VERSION ""

NS_ :

BS_:

BU_: IPC GWM BCM
VAL_TABLE_ TP_Data_Rq 15 "Data15" 14 "Data14" 13 "Data13" 12 "Data12" 11 "Data11" 10 "Data10" 9 "Data9" 8 "Data8" 7 "Data7" 6 "Data6" 5 "Data5" 4 "Data4" 3 "Data3" 2 "Data2" 1 "Data1" 0 "Unused" ;
VAL_TABLE_ TA_Data_Rq 3 "Unavailable" 2 "Available" 1 "None" 0 "Not_Used" ;
VAL_TABLE_ ENV_Menu_scrn_1_Data 3 "Not_Used" 2 "ON" 1 "OFF" 0 "No_Menu" ;
VAL_TABLE_ ENV_Artst_Name_1_Rq 7 "Artist7" 6 "Artist6" 5 "Artist5" 4 "Artist4" 3 "Artist3" 2 "Artist2" 1 "Artist1" 0 "Not_Used" ;
VAL_TABLE_ ENV_Radio_Txt_1_Rq 0 "No_Message" 1 "Message1" 2 "Message2" 3 "Message3" 4 "Message4" 5 "Message5" 6 "Message6" 7 "Message7" 8 "Message8" 9 "Message9" 10 "Message10" 11 "Message11" 12 "Message12" 13 "Message13" 14 "Message14" 15 "Message15" ;
VAL_TABLE_ ENV_OFF_RUN 1 "RUN" 0 "OFF" ;
VAL_TABLE_ ENV_Preset_6_Bank_Rq 0 "Preset_6_None" 1 "Preset_6_One" 2 "Preset_6_Two" 3 "Preset_6_Three" 4 "Preset_6_Four" 5 "Preset_6_Five" 6 "Preset_6_Six" 7 "Preset_6_Seven" ;
VAL_TABLE_ ENV_Preset_12_Bank_Rq 0 "Preset_12_None" 1 "Preset_12_One" 2 "Preset_12_Two" 3 "Preset_12_Three" 4 "Preset_12_Four" 5 "Preset_12_Five" 6 "Preset_12_Six" 7 "Preset_12_Seven" 8 "Preset_12_Eight" 9 "Preset_12_Nine" 10 "Preset_12_Ten" 11 "Preset_12_Eleven" 12 "Preset_12_Twelve" 13 "Not_Used1" 14 "Not_Used2" 15 "Not_Used3" ;
VAL_TABLE_ ENV_Unavailabe_Availabled 3 "Disabled" 2 "ON" 1 "OFF" 0 "Unavailable" ;
VAL_TABLE_ ENV_HMI_MID_Sgnl_3_Rq 0 "Zero_Sig_3" 1 "One_Sig_3" 2 "Two_Sig_3" 3 "Three_Sig_3" 4 "Four_Sig_3" 5 "Five_Sig_3" 6 "Six_Sig_3" 7 "Seven_Sig_3" 8 "Eight_Sig_3" 9 "Nine_Sig_3" 10 "Ten_Sig_3" 11 "Eleven_Sig_3" 12 "Twelve_Sig_3" 13 "Thirteen_Sig_3" 14 "Fourteen_Sig_3" 15 "Fifteen_Sig_3" ;
VAL_TABLE_ ENV_ON_OFF 1 "ON" 0 "OFF" ;
VAL_TABLE_ ENV_HMI_MID_Sgnl_2_Rq 15 "Fifteen_Sig_2" 14 "Fourteen_Sig_2" 13 "Thirteen_Sig_2" 12 "Twelve_Sig_2" 11 "Eleven_Sig_2" 10 "Ten_Sig_2" 9 "Nine_Sig_2" 8 "Eight_Sig_2" 7 "Seven_Sig_2" 6 "Six_Sig_2" 5 "Five_Sig_2" 4 "Four_Sig_2" 3 "Three_Sig_2" 2 "Two_Sig_2" 1 "One_Sig_2" 0 "Zero_Sig_2" ;
VAL_TABLE_ ENV_HMI_MID_Sgnl_1_Rq 15 "Fifteen_Sig_1" 14 "Fourteen_Sig_1" 13 "Thirteen_Sig_1" 12 "Twelve_Sig_1" 11 "Eleven_Sig_1" 10 "Ten_Sig_1" 9 "Nine_Sig_1" 8 "Eight_Sig_1" 7 "Seven_Sig_1" 6 "Six_Sig_1" 5 "Five_Sig_1" 4 "Four_Sig_1" 3 "Three_Sig_1" 2 "Two_Sig_1" 1 "One_Sig_1" 0 "Zero_Sig_1" ;

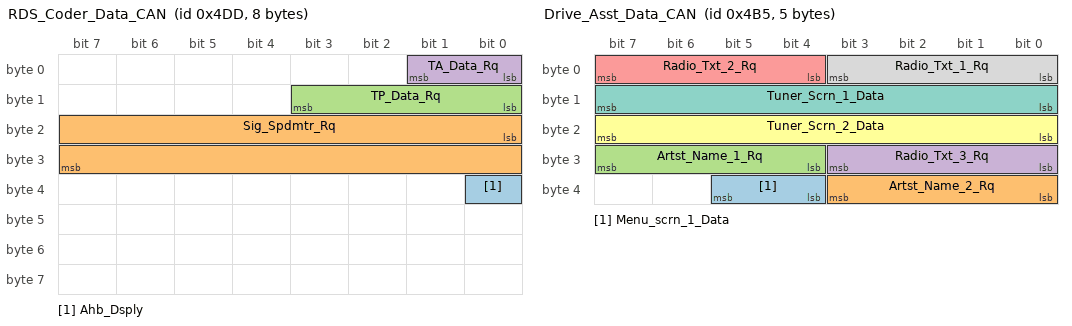
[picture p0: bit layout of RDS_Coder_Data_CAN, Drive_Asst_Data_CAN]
BO_ 1245 RDS_Coder_Data_CAN: 8 GWM
 SG_ Ahb_Dsply : 32|1@1+ (1,0) [0|1] ""  IPC
 SG_ Sig_Spdmtr_Rq : 16|16@1+ (1,0) [0|240] "SED"  IPC
 SG_ TP_Data_Rq : 8|4@1+ (1,0) [0|15] "SED"  IPC
 SG_ TA_Data_Rq : 0|2@1+ (1,0) [0|3] "SED"  IPC

BO_ 1205 Drive_Asst_Data_CAN: 5 BCM
 SG_ Menu_scrn_1_Data : 36|2@1+ (1,0) [0|3] "SED"  IPC
 SG_ Artst_Name_2_Rq : 32|4@1+ (1,0) [0|7] "SED"  IPC
 SG_ Artst_Name_1_Rq : 28|4@1+ (1,0) [0|7] "SED"  IPC
 SG_ Radio_Txt_3_Rq : 24|4@1+ (1,0) [0|15] "SED"  IPC
 SG_ Radio_Txt_2_Rq : 4|4@1+ (1,0) [0|15] "SED"  IPC
 SG_ Tuner_Scrn_2_Data : 16|8@1+ (1,0) [0|255] "Hz"  IPC
 SG_ Tuner_Scrn_1_Data : 8|8@1+ (1,0) [0|255] "Hz"  IPC
 SG_ Radio_Txt_1_Rq : 0|4@1+ (1,0) [0|15] "SED"  IPC

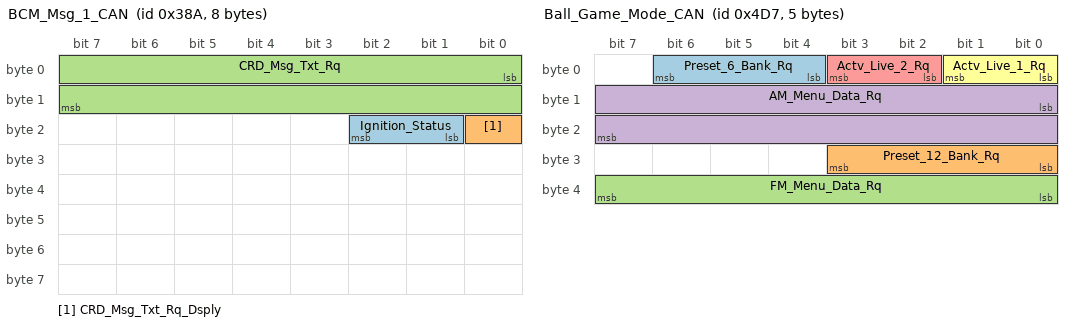
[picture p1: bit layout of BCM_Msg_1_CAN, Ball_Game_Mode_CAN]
BO_ 906 BCM_Msg_1_CAN: 8 BCM
 SG_ Ignition_Status : 17|2@1+ (1,0) [0|3] ""  IPC
 SG_ CRD_Msg_Txt_Rq_Dsply : 16|1@1+ (1,0) [0|1] "SED"  IPC
 SG_ CRD_Msg_Txt_Rq : 0|16@1+ (1,0) [0|65535] ""  IPC

BO_ 1239 Ball_Game_Mode_CAN: 5 GWM
 SG_ Preset_6_Bank_Rq : 4|3@1+ (1,0) [0|7] "SED"  IPC
 SG_ Preset_12_Bank_Rq : 24|4@1+ (1,0) [0|15] "SED"  IPC
 SG_ FM_Menu_Data_Rq : 32|8@1+ (1,0) [0|255] "SED"  IPC
 SG_ AM_Menu_Data_Rq : 8|16@1+ (1,0) [0|65535] ""  IPC
 SG_ Actv_Live_2_Rq : 2|2@1+ (1,0) [0|3] "SED"  IPC
 SG_ Actv_Live_1_Rq : 0|2@1+ (1,0) [0|3] "SED"  IPC

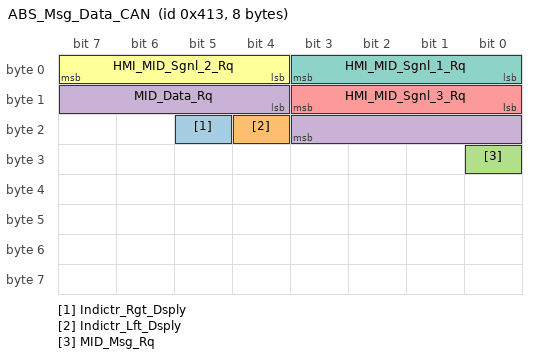
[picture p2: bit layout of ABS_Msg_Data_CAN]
BO_ 1043 ABS_Msg_Data_CAN: 8 GWM
 SG_ Indictr_Rgt_Dsply : 21|1@1+ (1,0) [0|1] ""  IPC
 SG_ Indictr_Lft_Dsply : 20|1@1+ (1,0) [0|1] ""  IPC
 SG_ MID_Msg_Rq : 24|1@1+ (1,0) [0|1] "SED"  IPC
 SG_ MID_Data_Rq : 12|8@1+ (1,0) [0|255] "range"  IPC
 SG_ HMI_MID_Sgnl_3_Rq : 8|4@1+ (1,0) [0|15] "SED"  IPC
 SG_ HMI_MID_Sgnl_2_Rq : 4|4@1+ (1,0) [0|15] "SED"  IPC
 SG_ HMI_MID_Sgnl_1_Rq : 0|4@1+ (1,0) [0|15] "SED"  IPC

BA_DEF_ BO_  "GenMsgCycleTime" INT 0 20000;
BA_DEF_ BO_  "GenMsgSendType" ENUM  "NA","Event","EventPeriodic","FixedPeriodic";
BA_DEF_DEF_  "GenMsgCycleTime" 0;
BA_DEF_DEF_  "GenMsgSendType" "NA";
BA_ "GenMsgSendType" BO_ 1245 1;
BA_ "GenMsgSendType" BO_ 1205 2;
BA_ "GenMsgCycleTime" BO_ 1205 1000;
BA_ "GenMsgSendType" BO_ 906 3;
BA_ "GenMsgCycleTime" BO_ 906 100;
BA_ "GenMsgSendType" BO_ 1239 3;
BA_ "GenMsgCycleTime" BO_ 1239 50;
BA_ "GenMsgSendType" BO_ 1043 2;
BA_ "GenMsgCycleTime" BO_ 1043 1500;
VAL_ 1245 Ahb_Dsply 1 "ON" 0 "OFF" ;
VAL_ 1245 TP_Data_Rq 15 "Data15" 14 "Data14" 13 "Data13" 12 "Data12" 11 "Data11" 10 "Data10" 9 "Data9" 8 "Data8" 7 "Data7" 6 "Data6" 5 "Data5" 4 "Data4" 3 "Data3" 2 "Data2" 1 "Data1" 0 "Unused" ;
VAL_ 1245 TA_Data_Rq 3 "Unavailable" 2 "Available" 1 "None" 0 "Not_Used" ;
VAL_ 1205 Menu_scrn_1_Data 3 "Not_Used" 2 "ON" 1 "OFF" 0 "No_Menu" ;
VAL_ 1205 Artst_Name_2_Rq 7 "Artist7" 6 "Artist6" 5 "Artist5" 4 "Artist4" 3 "Artist3" 2 "Artist2" 1 "Artist1" 0 "Not_Used" ;
VAL_ 1205 Artst_Name_1_Rq 7 "Artist7" 6 "Artist6" 5 "Artist5" 4 "Artist4" 3 "Artist3" 2 "Artist2" 1 "Artist1" 0 "Not_Used" ;
VAL_ 1205 Radio_Txt_3_Rq 0 "No_Message" 1 "Message1" 2 "Message2" 3 "Message3" 4 "Message4" 5 "Message5" 6 "Message6" 7 "Message7" 8 "Message8" 9 "Message9" 10 "Message10" 11 "Message11" 12 "Message12" 13 "Message13" 14 "Message14" 15 "Message15" ;
VAL_ 1205 Radio_Txt_2_Rq 0 "No_Message" 1 "Message1" 2 "Message2" 3 "Message3" 4 "Message4" 5 "Message5" 6 "Message6" 7 "Message7" 8 "Message8" 9 "Message9" 10 "Message10" 11 "Message11" 12 "Message12" 13 "Message13" 14 "Message14" 15 "Message15" ;
VAL_ 1205 Radio_Txt_1_Rq 0 "No_Message" 1 "Message1" 2 "Message2" 3 "Message3" 4 "Message4" 5 "Message5" 6 "Message6" 7 "Message7" 8 "Message8" 9 "Message9" 10 "Message10" 11 "Message11" 12 "Message12" 13 "Message13" 14 "Message14" 15 "Message15" ;
VAL_ 906 CRD_Msg_Txt_Rq_Dsply 1 "ON" 0 "OFF" ;
VAL_ 1239 Preset_6_Bank_Rq 0 "Preset_6_None" 1 "Preset_6_One" 2 "Preset_6_Two" 3 "Preset_6_Three" 4 "Preset_6_Four" 5 "Preset_6_Five" 6 "Preset_6_Six" 7 "Preset_6_Seven" ;
VAL_ 1239 Preset_12_Bank_Rq 0 "Preset_12_None" 1 "Preset_12_One" 2 "Preset_12_Two" 3 "Preset_12_Three" 4 "Preset_12_Four" 5 "Preset_12_Five" 6 "Preset_12_Six" 7 "Preset_12_Seven" 8 "Preset_12_Eight" 9 "Preset_12_Nine" 10 "Preset_12_Ten" 11 "Preset_12_Eleven" 12 "Preset_12_Twelve" 13 "Not_Used1" 14 "Not_Used2" 15 "Not_Used3" ;
VAL_ 1239 Actv_Live_2_Rq 3 "Disabled" 2 "ON" 1 "OFF" 0 "Unavailable" ;
VAL_ 1239 Actv_Live_1_Rq 3 "Disabled" 2 "ON" 1 "OFF" 0 "Unavailable" ;
VAL_ 1043 Indictr_Rgt_Dsply 1 "ON" 0 "OFF" ;
VAL_ 1043 Indictr_Lft_Dsply 1 "ON" 0 "OFF" ;
VAL_ 1043 HMI_MID_Sgnl_3_Rq 0 "Zero_Sig_3" 1 "One_Sig_3" 2 "Two_Sig_3" 3 "Three_Sig_3" 4 "Four_Sig_3" 5 "Five_Sig_3" 6 "Six_Sig_3" 7 "Seven_Sig_3" 8 "Eight_Sig_3" 9 "Nine_Sig_3" 10 "Ten_Sig_3" 11 "Eleven_Sig_3" 12 "Twelve_Sig_3" 13 "Thirteen_Sig_3" 14 "Fourteen_Sig_3" 15 "Fifteen_Sig_3" ;
VAL_ 1043 HMI_MID_Sgnl_2_Rq 15 "Fifteen_Sig_2" 14 "Fourteen_Sig_2" 13 "Thirteen_Sig_2" 12 "Twelve_Sig_2" 11 "Eleven_Sig_2" 10 "Ten_Sig_2" 9 "Nine_Sig_2" 8 "Eight_Sig_2" 7 "Seven_Sig_2" 6 "Six_Sig_2" 5 "Five_Sig_2" 4 "Four_Sig_2" 3 "Three_Sig_2" 2 "Two_Sig_2" 1 "One_Sig_2" 0 "Zero_Sig_2" ;
VAL_ 1043 HMI_MID_Sgnl_1_Rq 15 "Fifteen_Sig_1" 14 "Fourteen_Sig_1" 13 "Thirteen_Sig_1" 12 "Twelve_Sig_1" 11 "Eleven_Sig_1" 10 "Ten_Sig_1" 9 "Nine_Sig_1" 8 "Eight_Sig_1" 7 "Seven_Sig_1" 6 "Six_Sig_1" 5 "Five_Sig_1" 4 "Four_Sig_1" 3 "Three_Sig_1" 2 "Two_Sig_1" 1 "One_Sig_1" 0 "Zero_Sig_1" ;
